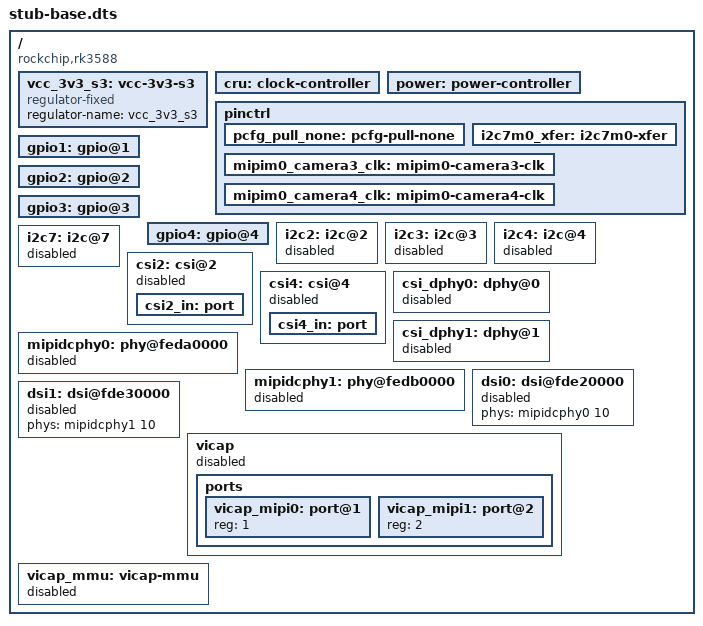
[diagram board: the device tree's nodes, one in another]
/dts-v1/;

/ {
	compatible = "rockchip,rk3588";
	#address-cells = <2>;
	#size-cells = <2>;

	vcc_3v3_s3: vcc-3v3-s3 {
		compatible = "regulator-fixed";
		regulator-name = "vcc_3v3_s3";
	};

	cru: clock-controller {
		#clock-cells = <1>;
	};

	power: power-controller {
		#power-domain-cells = <1>;
	};

	pinctrl: pinctrl {
		pcfg_pull_none: pcfg-pull-none {
		};
		i2c7m0_xfer: i2c7m0-xfer {
		};
		mipim0_camera3_clk: mipim0-camera3-clk {
		};
		mipim0_camera4_clk: mipim0-camera4-clk {
		};
	};

	gpio1: gpio@1 {
		#gpio-cells = <2>;
	};
	gpio2: gpio@2 {
		#gpio-cells = <2>;
	};
	gpio3: gpio@3 {
		#gpio-cells = <2>;
	};
	gpio4: gpio@4 {
		#gpio-cells = <2>;
	};

	i2c2: i2c@2 {
		#address-cells = <1>;
		#size-cells = <0>;
		status = "disabled";
	};
	i2c3: i2c@3 {
		#address-cells = <1>;
		#size-cells = <0>;
		status = "disabled";
	};
	i2c4: i2c@4 {
		#address-cells = <1>;
		#size-cells = <0>;
		status = "disabled";
	};
	i2c7: i2c@7 {
		#address-cells = <1>;
		#size-cells = <0>;
		status = "disabled";
	};

	/* Stock DTBs have no csi0/csi1; the port2/port3 overlays add them. */
	csi2: csi@2 {
		status = "disabled";
		csi2_in: port {
		};
	};
	csi4: csi@4 {
		status = "disabled";
		csi4_in: port {
		};
	};

	csi_dphy0: dphy@0 {
		status = "disabled";
	};
	csi_dphy1: dphy@1 {
		status = "disabled";
	};

	mipidcphy0: phy@feda0000 {
		#phy-cells = <1>;
		status = "disabled";
	};
	mipidcphy1: phy@fedb0000 {
		#phy-cells = <1>;
		status = "disabled";
	};

	dsi0: dsi@fde20000 {
		phys = <&mipidcphy0 10>;
		status = "disabled";
	};
	dsi1: dsi@fde30000 {
		phys = <&mipidcphy1 10>;
		status = "disabled";
	};

	vicap: vicap {
		status = "disabled";

		ports {
			#address-cells = <1>;
			#size-cells = <0>;

			vicap_mipi0: port@1 {
				reg = <1>;
			};
			vicap_mipi1: port@2 {
				reg = <2>;
			};
		};
	};
	vicap_mmu: vicap-mmu {
		status = "disabled";
	};
};
